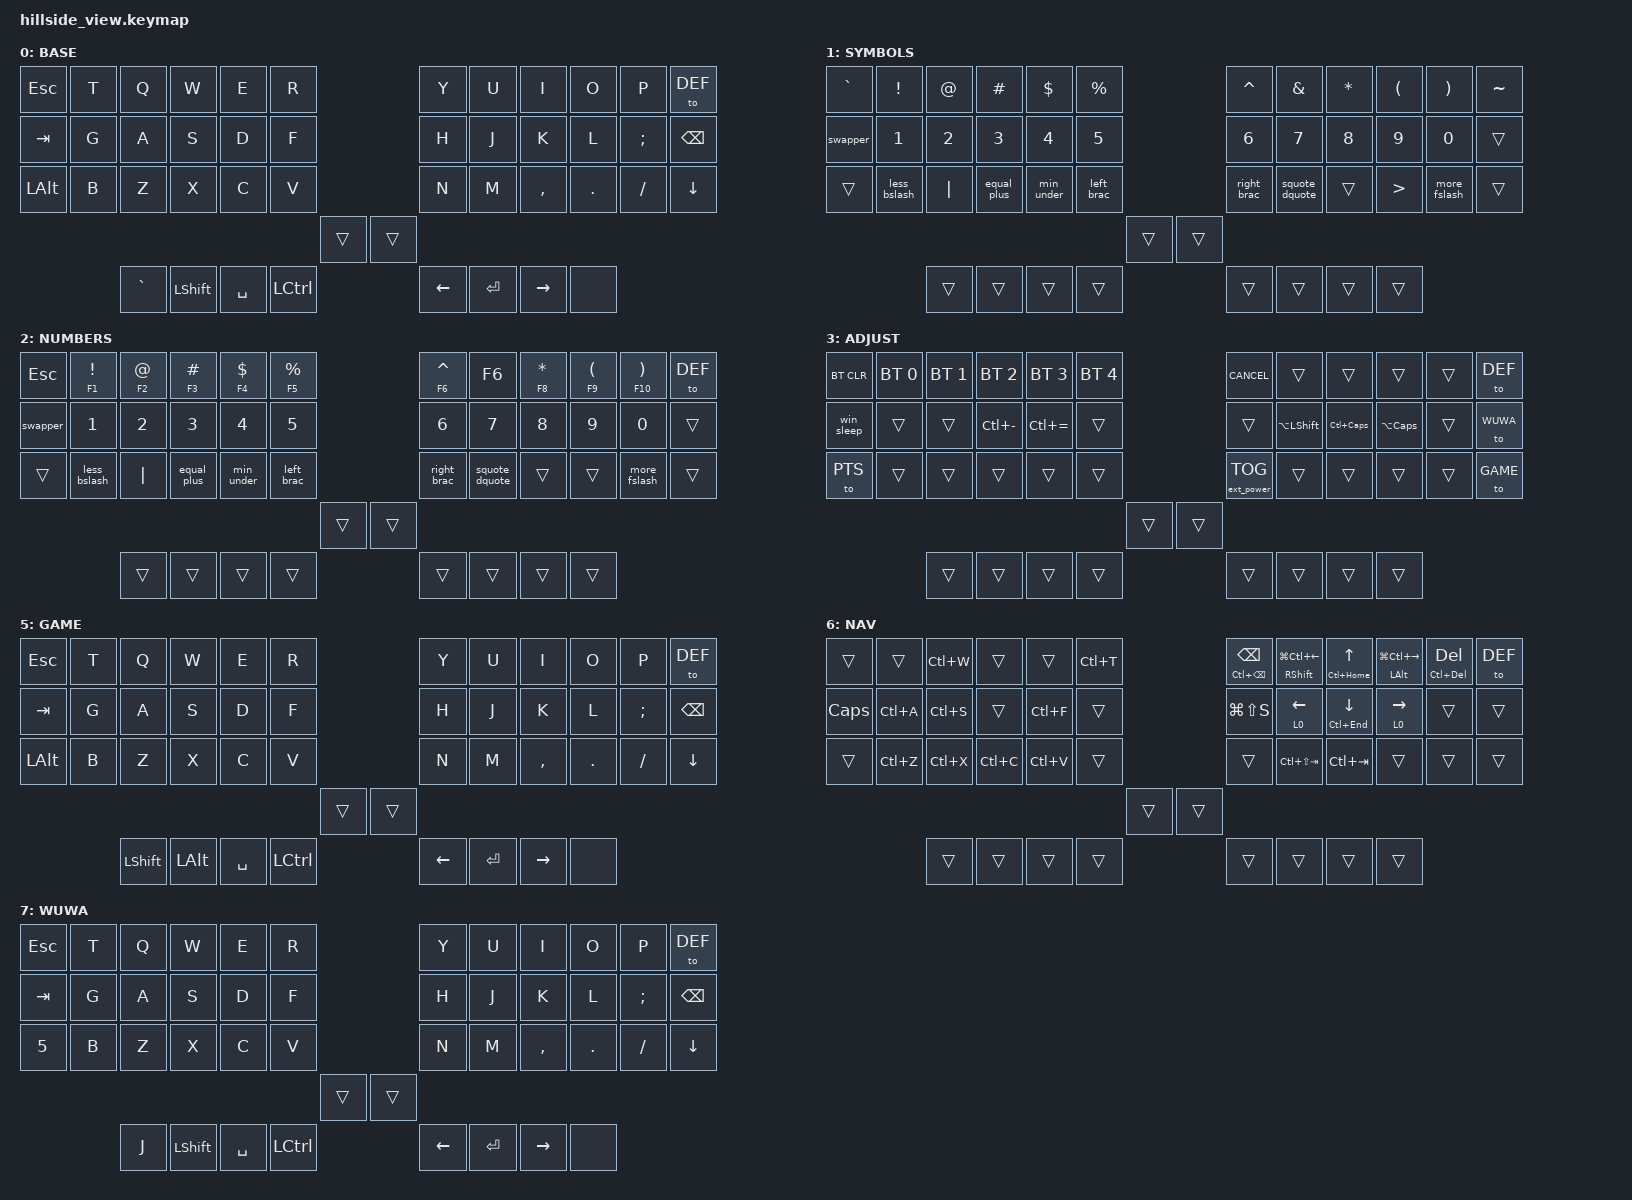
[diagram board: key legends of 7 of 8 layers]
#include <behaviors.dtsi>
#include <dt-bindings/zmk/keys.h>
#include <dt-bindings/zmk/bt.h>
#include <dt-bindings/zmk/rgb.h>
#include <dt-bindings/zmk/ext_power.h>
#include <dt-bindings/zmk/outputs.h>

#include "helpers.h"
#include "../zmk-nodefree-config/helper.h"
#include "../zmk-nodefree-config/keypos_def/keypos_46keys_hillside.h"

// #include "combos.dtsi"
#include "pts.dtsi"
#include "mouse.dtsi"

/* Defines */

#define XXX &none
#define ___ &trans

#define QUICK_TAP_MS 175

&sk {  // sticky-key config
    release-after-ms = <900>;  // release after 0.6s
    quick-release;             // no double capitalization when rolling keys
};

&sl {  // sticky-layer config
    ignore-modifiers;          // allow chording sticky mods & layers
};

&lt {  // layer-tap config
    flavor = "balanced";
    tapping-term-ms = <200>;
    quick-tap-ms = <QUICK_TAP_MS>;
};



// Layes. If you need to modify layers it's easier to refer to them via names, such as SYM for symbol and NUM for numbrs.
// Alias your layers with names in the section below
#define DEF 0
#define SYM 1
#define NUM 2
#define ADJ 3
#define PTS 4
#define GAME 5
#define WUWA 7
#define NAV 6


/* End of Defines */


// Q: What are those things starting with &? 
// A: Keywords that start with & are "behaviors". Behaviors are the main way to configure your keymap. 
//    The most common is called &kp which stands for key press. There several built-in bevaiors and also unlimitted number of ones you can create.
// Q: What are available built-in bevaiors?
// A: Here is a list of most common ones:
//   &kp - key press
//   &mo - momentary turn on the layer
//   &to - toggle a layer
//   &lt - layer tap; tap for a key pres and hold for a layer
//   &mt - mod tap; hold for modifier, tap for a key press
//   &sk - sticky key; sticky modifier



/*                                      46 KEY MATRIX / LAYOUT MAPPING

  ╭────────────────────────╮               ╭────────────────────────╮
  │  0   1   2   3   4   5 │               │  6   7   8   9  10  11 │
  │ 12  13  14  15  16  17 ╰──╮         ╭──╯ 18  19  20  21  22  23 │
  │ 24  25  26  27  28  29  36╰────┬────╯37  30  31  32  33  34  35 │
  ╰───────────────╮ 38  39  40  41 │ 42  43  44  45 ╭───────────────╯
                  ╰────────────────┴────────────────╯
                  
 ╭─────────────────────────╮               ╭─────────────────────────╮
 │ LT5 LT4 LT3 LT2 LT1 LT0 │               │ RT0 RT1 RT2 RT3 RT4 RT5 │
 │ LM5 LM4 LM3 LM2 LM1 LM0 ╰──╮         ╭──╯ RM0 RM1 RM2 RM3 RM4 RM5 │
 │ LB5 LB4 LB3 LB2 LB1 LB0 LH4╰────┬────╯RH4 RB0 RB1 RB2 RB3 RB4 RB5 │
 ╰───────────────╮ LH3 LH2 LH1 LH0 │ RH0 RH1 RH2 RH3 ╭───────────────╯
                 ╰─────────────────┴───── ───────────╯
 T : Top
 M : Middle
 B : Bottom
 H : Hand
 P : Palm
*/

#undef COMBO_HOOK
#define COMBO_HOOK global-quick-tap-ms = <150>;

#define COMBO_TERM_FAST 18
#define COMBO_TERM_SLOW 30
#define COMBO_TERM_SLOWW 90

// make homerow combos tap-only (so HRMs can be chorded instantaneously)
// #define HRC_TAB    &hml         LA(LCTRL) TAB
// #define HRC_REPEAT &hml_repeat  LS(LCTRL) 0
// #define HRC_LPAR   &hmr_lpar_lt RS(LCTRL) 0
// #define HRC_RPAR   &hmr_rpar_gt LA(LCTRL) 0



/* Horizontal combos - left hand */
// ZMK_COMBO(lpar,  &kp LPAR,      LM1 LM2,     DEF SYM NUM, COMBO_TERM_SLOWW)
// ZMK_COMBO(minus, &kp MINUS,     LM2 LM3,     DEF SYM NUM, COMBO_TERM_SLOWW)

/* Horizontal combos - right hand */
// ZMK_COMBO(rpar,  &kp RPAR,      RM1 RM2,     DEF SYM NUM, COMBO_TERM_SLOWW)
// ZMK_COMBO(sqt,   &kp SQT,       RM2 RM3,     DEF SYM NUM, COMBO_TERM_SLOWW)
// ZMK_COMBO(dqt,   &kp DQT,       RM3 RM4,     DEF SYM NUM, COMBO_TERM_SLOWW)


/* Vertical combos - left hand */
// ZMK_COMBO(excl,  &kp EXCL,      LT4 LM4,     DEF     NUM, COMBO_TERM_SLOW)
// ZMK_COMBO(at,    &kp AT,        LT3 LM3,     DEF     NUM, COMBO_TERM_SLOW)
// ZMK_COMBO(hash,  &kp POUND,     LT2 LM2,     DEF     NUM, COMBO_TERM_SLOW)
// ZMK_COMBO(dllr,  &kp DLLR,      LT1 LM1,     DEF     NUM, COMBO_TERM_SLOW)
// ZMK_COMBO(prcnt, &kp PRCNT,     LT0 LM0,     DEF     NUM, COMBO_TERM_SLOW)

// ZMK_COMBO(grave, &kp EQUAL,     LM4 LB4,     DEF     NUM, COMBO_TERM_SLOW)
// ZMK_COMBO(bslh,  &kp BSLH,      LM3 LB3,     DEF     NUM, COMBO_TERM_SLOW)
//  ZMK_COMBO(under, &kp UNDER,     LM2 LB2,     DEF     NUM, COMBO_TERM_SLOW)
//  ZMK_COMBO(minus, &kp MINUS,     LM1 LB1,     DEF     NUM, COMBO_TERM_SLOW)
// ZMK_COMBO(tilde, &kp CARET,  LM0 LB0,     DEF     NUM, COMBO_TERM_SLOW)

/* Vertical combos - right hand */
// ZMK_COMBO(caret, &kp CARET,     RT0 RM0,     DEF     NUM, COMBO_TERM_SLOW)
// ZMK_COMBO(amps,  &kp AMPS,      RT1 RM1,     DEF     NUM, COMBO_TERM_SLOW)
// ZMK_COMBO(astrk, &kp ASTRK,     RT2 RM2,     DEF     NUM, COMBO_TERM_SLOW)
// ZMK_COMBO(plus,  &kp PLUS,      RT3 RM3,     DEF     NUM, COMBO_TERM_SLOW)
// ZMK_COMBO(equal, &kp EQUAL,     RT4 RM4,     DEF     NUM, COMBO_TERM_SLOW)

// ZMK_COMBO(under, &kp UNDER,     RM0 RB0,     DEF     NUM, COMBO_TERM_SLOW)
//  ZMK_COMBO(sqt,     &kp SQT,     RM1 RB1,     DEF     NUM, COMBO_TERM_SLOW)
//  ZMK_COMBO(dqt,     &kp DQT,     RM2 RB2,     DEF     NUM, COMBO_TERM_SLOW)
// ZMK_COMBO(fslh,    &kp FSLH,    RM3 RB3,     DEF     NUM, COMBO_TERM_SLOW)
// ZMK_COMBO(under, &kp UNDER,     RM4 RB4,     DEF     NUM, COMBO_TERM_SLOW)


  /* Homerow mods */

#define KEYS_L LT0 LT1 LT2 LT3 LT4 LT5 LM0 LM1 LM2 LM3 LM4 LM5 LB0 LB1 LB2 LB3 LB4 LB5 // left hand
#define KEYS_R RT0 RT1 RT2 RT3 RT4 RT5 RM0 RM1 RM2 RM3 RM4 RM5 RB0 RB1 RB2 RB3 RB4 RB5 // right hand
#define THUMBS LH4 LH3 LH2 LH1 LH0 RH0 RH1 RH2 RH3 RH4                                     // thumbs

#define MAKE_HRM(NAME, HOLD, TAP, TRIGGER_POS) \
    ZMK_BEHAVIOR(NAME, hold_tap, \
        flavor = "balanced"; \
        tapping-term-ms = <280>; \
        quick-tap-ms = <QUICK_TAP_MS>; \
        global-quick-tap-ms = <150>; \
        bindings = <HOLD>, <TAP>; \
        hold-trigger-key-positions = <TRIGGER_POS>; \
        hold-trigger-on-release; \
    )
MAKE_HRM(hml, &kp, &kp, KEYS_R THUMBS)  // left-hand HRMs
MAKE_HRM(hmr, &kp, &kp, KEYS_L THUMBS)  // right-hand HRMs


/* Caps-word, num-word */

// tap: sticky-shift | shift + tap/ double-tap: caps-word | hold: shift
ZMK_BEHAVIOR(smart_shft, mod_morph,
    bindings = <&sk LSHFT>, <&caps_word>;
    mods = <(MOD_LSFT)>;
)
&caps_word {  // mods deactivate caps-word, requires PR #1451
    /delete-property/ ignore-modifiers;
};

// tap: num-word | double-tap: sticky num-layer | hold: num-layer
#define SMART_NUM &smart_num NUM 0
ZMK_BEHAVIOR(smart_num, hold_tap,
    flavor = "balanced";
    tapping-term-ms = <200>;
    quick-tap-ms = <QUICK_TAP_MS>;
    bindings = <&mo>, <&num_dance>;
)
ZMK_BEHAVIOR(num_dance, tap_dance,
    tapping-term-ms = <200>;
    bindings = <&num_word>, <&sl NUM>;  // reverse this for sticky-num on single tap
)
&num_word {  // num-word, requires PR #1451
    layers = <NUM>;
    continue-list = <BSPC DEL DOT COMMA PLUS MINUS STAR FSLH EQUAL>;
};


// tap: space | shift + tap: dot -> space -> sticky shift | hold: activate layer
/*
ZMK_BEHAVIOR(lt_spc, hold_tap,
    flavor = "balanced";
    tapping-term-ms = <200>;
    quick-tap-ms = <QUICK_TAP_MS>;
    bindings = <&mo>, <&spc_morph>;
)
*/

ZMK_BEHAVIOR(lt_spc, mod_morph,
    bindings = <&kp SPACE>, <&spc_morph>;
    mods = <(MOD_LSFT|MOD_RSFT)>;
)
ZMK_BEHAVIOR(spc_morph, mod_morph,
    bindings = <&kp SPACE>, <&dot_spc>;
    mods = <(MOD_LSFT|MOD_RSFT)>;
)
ZMK_BEHAVIOR(dot_spc, macro,
    wait-ms = <0>;
    tap-ms = <5>;
    bindings = <&kp DOT &kp SPACE &sk LSHFT>;
)


/* Nav cluster */

// long-tap action on hold, short-tap action on all interrupts
#define MT_CORE \
    flavor = "tap-preferred"; \
    tapping-term-ms = <220>; \
    quick-tap-ms = <220>; \
    hold-trigger-key-positions = <0>;

&mt { MT_CORE };
ZMK_BEHAVIOR(mt_home, hold_tap, bindings = <&masked_home>, <&kp>; MT_CORE)
ZMK_BEHAVIOR(mt_end,  hold_tap,  bindings = <&masked_end>, <&kp>; MT_CORE)

#define NAV_LEFT  &mt_home 0   LEFT    // tap: left  | long-tap: beginning of line
#define NAV_RIGHT &mt_end 0    RIGHT   // tap: right | long-tap: end       of line
#define NAV_UP    &mt LC(HOME) UP      // tap: up    | long-tap: beginning of document
#define NAV_DOWN  &mt LC(END)  DOWN    // tap: down  | long-tap: end       of document
#define NAV_BSPC  &mt LC(BSPC) BSPC    // tap: bspc  | long-tap: delete word backward
#define NAV_DEL   &mt LC(DEL)  DEL     // tap: del   | long-tap: delete word forward

// mask CTRL when holding left/right to avoid accidental jumps to beginning/end of document
#define MASK_MODS(NAME, MODS, BINDING) \
    ZMK_BEHAVIOR(NAME, mod_morph, \
        bindings = <BINDING>, <BINDING>; \
        mods = <MODS>; \
    )
MASK_MODS(masked_home, (MOD_LCTL), &kp HOME)
MASK_MODS(masked_end,  (MOD_LCTL), &kp END)


  /* Custom behaviors */

// tap: left-parenthesis | shft + tap: less-than
ZMK_BEHAVIOR(lpar_lt, mod_morph,
    bindings = <&kp LPAR>, <&kp LT>;
    mods = <(MOD_LSFT|MOD_RSFT)>;
)

// tap: right-parenthesis | shft + tap: greater-than
ZMK_BEHAVIOR(rpar_gt, mod_morph,
    bindings = <&kp RPAR>, <&kp GT>;
    mods = <(MOD_LSFT|MOD_RSFT)>;
)

ZMK_BEHAVIOR(win_sleep, macro,
    wait-ms = <500>;
    tap-ms = <50>;
    bindings = <&kp LG(X) &kp U &kp S>;
)

ZMK_BEHAVIOR(min_under, tap_dance,
    tapping-term-ms = <300>;
    bindings = <&kp MINUS>, <&kp UNDERSCORE>;
)
ZMK_BEHAVIOR(equal_plus, tap_dance,
    tapping-term-ms = <300>;
    bindings = <&kp EQUAL>, <&kp PLUS>;
)
ZMK_BEHAVIOR(squote_dquote, tap_dance,
    tapping-term-ms = <300>;
    bindings = <&kp SQT>, <&kp DQT>;
)
ZMK_BEHAVIOR(left_brac, tap_dance,
    tapping-term-ms = <300>;
    bindings = <&kp LEFT_BRACKET>, <&kp LEFT_BRACE>;
)
ZMK_BEHAVIOR(right_brac, tap_dance,
    tapping-term-ms = <300>;
    bindings = <&kp RIGHT_BRACKET>, <&kp RIGHT_BRACE>;
)
ZMK_BEHAVIOR(less_bslash, tap_dance,
    tapping-term-ms = <300>;
    bindings = <&kp LESS_THAN>, <&kp BACKSLASH>;
)
ZMK_BEHAVIOR(more_fslash, tap_dance,
    tapping-term-ms = <300>;
    bindings = <&kp GT>, <&kp FSLH>;
)


// Alt+Tab swapper, requires PR #1366
ZMK_BEHAVIOR(swapper, tri_state,
    bindings = <&kt LALT>, <&kp TAB>, <&kt LALT>;
    ignored-key-positions = <LT2>;
)

  // misc aliases
#define CANCEL      &kp K_CANCEL             // cancel caps-word, num-word
#define DSK_PREV    &hmr RSHFT LG(LC(LEFT))  // previous desktop
#define DSK_NEXT    &hmr LALT LG(LC(RIGHT))  // next     desktop

// ZMK_CONDITIONAL_LAYER(SYM NUM, ADJ)  // SYM + NUM --> ADJ

/ {
  
  conditional_layers {
    compatible = "zmk,conditional-layers";
    tri_layer {
      if-layers = <SYM NUM>;
      then-layer = <ADJ>;
    };
  };

  behaviors {
    // Hold tap behavior which will allow us to have a different key whether the key is tapped or held
    // https://zmk.dev/docs/behaviors/hold-tap
    ht: hold_tap {
      compatible = "zmk,behavior-hold-tap";
      label = "HOLD_TAP";
      #binding-cells = <2>;
      tapping_term_ms = <200>;
      quick_tap_ms = <200>;
      flavor = "tap-preferred";
      bindings = <&kp>, <&kp>;
    };
  };

  keymap {
    compatible = "zmk,keymap";
    default_layer {
      label = "BASE";
      bindings = <


/*
      // ╭─────────────┬─────────────┬─────────────┬─────────────┬─────────────┬─────────────╮                                      ╭─────────────┬─────────────┬─────────────┬─────────────┬─────────────┬────────────╮
             &kp ESC        &kp Q         &kp W         &kp E         &kp R         &kp T                                                &kp Y         &kp U         &kp I         &kp O        &kp P        &kp DEL    
      // ├─────────────┼─────────────┼─────────────┼─────────────┼─────────────┼─────────────┤                                      ├─────────────┼─────────────┼─────────────┼─────────────┼─────────────┼────────────┤
             &kp TAB     &hml LSHFT A  &hml LALT S   &hml LCTRL D  &hml LGUI F      &kp G                                                &kp H      &hmr RGUI J   &hmr RCTRL K  &hmr RALT L &hmr RSHFT SEMI  &kp BSPC    
      // ├─────────────┼─────────────┼─────────────┼─────────────┼─────────────┼─────────────┤  ╭─────────────╮     ╭─────────────╮ ├─────────────┼─────────────┼─────────────┼─────────────┼─────────────┼────────────┤
              &kp UP         &kp Z         &kp X         &kp C         &kp V        &kp B                                                &kp N         &kp M        &kp COMMA    &kp PERIOD     &kp FSLH     &kp DOWN  
                                                                                                      ___                 ___                                                                                         
      // ╰─────────────┴─────────────┼─────────────┼─────────────┼─────────────┼─────────────┤  ╰─────────────╯     ╰─────────────╯ ├─────────────┼─────────────┼─────────────┼─────────────┼─────────────┴────────────╯
                                         &mo NAV       &mo SYM      &kp ENTER    &smart_shft                                            &kp LEFT      &lt_spc      SMART_NUM     &kp RIGHT
      //                             ╰─────────────┴─────────────┴─────────────┴─────────────╯                                      ╰─────────────┴─────────────┴─────────────┴─────────────╯
      >;
*/

      // ╭─────────────┬─────────────┬─────────────┬─────────────┬─────────────┬─────────────╮                                      ╭─────────────┬─────────────┬─────────────┬─────────────┬─────────────┬────────────╮
             &kp ESC        &kp T         &kp Q         &kp W         &kp E         &kp R                                                &kp Y         &kp U         &kp I         &kp O        &kp P        &to DEF    
      // ├─────────────┼─────────────┼─────────────┼─────────────┼─────────────┼─────────────┤                                      ├─────────────┼─────────────┼─────────────┼─────────────┼─────────────┼────────────┤
             &kp TAB        &kp G         &kp A         &kp S         &kp D         &kp F                                                &kp H         &kp J         &kp K         &kp L        &kp SEMI     &kp BSPC    
      // ├─────────────┼─────────────┼─────────────┼─────────────┼─────────────┼─────────────┤  ╭─────────────╮     ╭─────────────╮ ├─────────────┼─────────────┼─────────────┼─────────────┼─────────────┼────────────┤
             &kp LALT       &kp B          &kp Z         &kp X        &kp C         &kp V                                                &kp N         &kp M        &kp COMMA     &kp DOT       &kp FSLH     &kp DOWN  
                                                                                                      ___                 ___                                                                                         
      // ╰─────────────┴─────────────┼─────────────┼─────────────┼─────────────┼─────────────┤  ╰─────────────╯     ╰─────────────╯ ├─────────────┼─────────────┼─────────────┼─────────────┼─────────────┴────────────╯
                                         &kp GRAVE    &kp LSHFT     &kp SPACE     &kp LCTRL                                              &kp LEFT     &kp ENTER     &kp RIGHT        XXX
      //                             ╰─────────────┴─────────────┴─────────────┴─────────────╯                                      ╰─────────────┴─────────────┴─────────────┴─────────────╯
      >;

      // Bindings for encoders, if you don't have encoders you can remove this line from all layers. If you leave it here it won't affect your keymap.
      sensor-bindings = <&inc_dec_kp C_VOL_DN C_VOL_UP &inc_dec_kp PG_UP PG_DN>;
    };
    sym_layer {
      label = "SYMBOLS";
      bindings = <
      // ╭─────────────┬─────────────┬─────────────┬─────────────┬─────────────┬─────────────╮                                      ╭─────────────┬─────────────┬─────────────┬─────────────┬─────────────┬────────────╮
	    &kp GRAVE     &kp EXCL       &kp AT      &kp POUND      &kp DLLR     &kp PRCNT                                            &kp CARET      &kp AMPS     &kp ASTRK      &kp LPAR      &kp RPAR      &kp TILDE
      // ├─────────────┼─────────────┼─────────────┼─────────────┼─────────────┼─────────────┤                                      ├─────────────┼─────────────┼─────────────┼─────────────┼─────────────┼────────────┤
             &swapper       &kp N1         &kp N2        &kp N3       &kp N4        &kp N5                                               &kp N6        &kp N7         &kp N8        &kp N9        &kp N0         ___
      // ├─────────────┼─────────────┼─────────────┼─────────────┼─────────────┼─────────────┤  ╭─────────────╮     ╭─────────────╮ ├─────────────┼─────────────┼─────────────┼─────────────┼─────────────┼────────────┤
               ___       &less_bslash    &kp PIPE    &equal_plus    &min_under    &left_brac                                          &right_brac  &squote_dquote     ___          &kp GT     &more_fslash      ___                                                                                                         ___                ___                                                                                          
      // ╰─────────────┴─────────────┼─────────────┼─────────────┼─────────────┼─────────────┤  ╰─────────────╯     ╰─────────────╯ ├─────────────┼─────────────┼─────────────┼─────────────┼─────────────┴────────────╯
                                           ___           ___           ___           ___                                                 ___          ___            ___           ___         
      //                             ╰─────────────┴─────────────┴─────────────┴─────────────╯                                      ╰─────────────┴─────────────┴─────────────┴─────────────╯
      >;
      sensor-bindings = <&inc_dec_kp C_VOL_DN C_VOL_UP &inc_dec_kp PG_UP PG_DN>;
    };
    num_layer {
      label = "NUMBERS";
      bindings = <
      // ╭─────────────┬─────────────┬─────────────┬─────────────┬─────────────┬─────────────╮                                      ╭─────────────┬─────────────┬─────────────┬─────────────┬─────────────┬────────────╮
             &kp ESC     &ht F1 EXCL    &ht F2 AT    &ht F3 POUND  &ht F4 DLLR  &ht F5 PRCNT                                          &ht F6 CARET  &kp F6  &ht F8 ASTRK   &ht F9 LPAR   &ht F10 RPAR    &to DEF
      // ├─────────────┼─────────────┼─────────────┼─────────────┼─────────────┼─────────────┤                                      ├─────────────┼─────────────┼─────────────┼─────────────┼─────────────┼────────────┤
            &swapper        &kp N1        &kp N2        &kp N3        &kp N4       &kp N5                                                &kp N6        &kp N7        &kp N8        &kp N9        &kp N0         ___
      // ├─────────────┼─────────────┼─────────────┼─────────────┼─────────────┼─────────────┤  ╭─────────────╮     ╭─────────────╮ ├─────────────┼─────────────┼─────────────┼─────────────┼─────────────┼────────────┤
               ___       &less_bslash    &kp PIPE    &equal_plus    &min_under    &left_brac                                          &right_brac  &squote_dquote     ___           ___       &more_fslash      ___                                                                                                        ___                ___                                                                                          
      // ╰─────────────┴─────────────┼─────────────┼─────────────┼─────────────┼─────────────┤  ╰─────────────╯     ╰─────────────╯ ├─────────────┼─────────────┼─────────────┼─────────────┼─────────────┴────────────╯
                                           ___            ___           ___           ___                                                ___          ___            ___           ___         
      //                             ╰─────────────┴─────────────┴─────────────┴─────────────╯                                      ╰─────────────┴─────────────┴─────────────┴─────────────╯
      >;
      sensor-bindings = <&inc_dec_kp C_VOL_DN C_VOL_UP &inc_dec_kp PG_UP PG_DN>;
    };
    adj_layer {
      label = "ADJUST";
      bindings = <
      // ╭─────────────┬─────────────┬─────────────┬─────────────┬─────────────┬─────────────╮                                      ╭─────────────┬─────────────┬─────────────┬─────────────┬─────────────┬────────────╮
           &bt BT_CLR  &bt BT_SEL 0    &bt BT_SEL 1 &bt BT_SEL 2  &bt BT_SEL 3  &bt BT_SEL 4                                             CANCEL         ___           ___           ___           ___        &to DEF
      // ├─────────────┼─────────────┼─────────────┼─────────────┼─────────────┼─────────────┤                                      ├─────────────┼─────────────┼─────────────┼─────────────┼─────────────┼────────────┤
	   &win_sleep        ___           ___      &kp LC(MINUS) &kp LC(EQUAL)      ___                                                  ___      &kp LA(LSHFT)  &kp LC(CAPS)  &kp LA(CAPS)      ___        &to WUWA
      // ├─────────────┼─────────────┼─────────────┼─────────────┼─────────────┼─────────────┤  ╭─────────────╮     ╭─────────────╮ ├─────────────┼─────────────┼─────────────┼─────────────┼─────────────┼────────────┤
             &to PTS         ___           ___           ___           ___           ___                                           &ext_power EP_TOG    ___           ___           ___           ___        &to GAME
                                                                                                      ___                ___                                                                                    
      // ╰─────────────┴─────────────┼─────────────┼─────────────┼─────────────┼─────────────┤  ╰─────────────╯     ╰─────────────╯ ├─────────────┼─────────────┼─────────────┼─────────────┼─────────────┴────────────╯
                                           ___           ___           ___           ___                                                  ___           ___           ___           ___           
      //                             ╰─────────────┴─────────────┴─────────────┴─────────────╯                                      ╰─────────────┴─────────────┴─────────────┴─────────────╯
      >;
      sensor-bindings = <&inc_dec_kp C_VOL_DN C_VOL_UP &inc_dec_kp PG_UP PG_DN>;
    };
    pts_layer {
      label = "PTS";
      bindings = <
      // ╭─────────────┬─────────────┬─────────────┬─────────────┬─────────────┬─────────────╮                                      ╭─────────────┬─────────────┬─────────────┬─────────────┬─────────────┬────────────╮
            &kp LC(S)     &dup_merge   &transf_warp   &move_full   &soft_vivid  &multiply_screen                                        &kp LC(K)       U_WH_U        U_MS_U        U_WH_D         &kp F       &to DEF
      // ├─────────────┼─────────────┼─────────────┼─────────────┼─────────────┼─────────────┤                                      ├─────────────┼─────────────┼─────────────┼─────────────┼─────────────┼────────────┤
	  &kp LC(LA(Q)) &kp new_layer     &kp L        &kp Z       &ht GRAVE B      &kp O                                               &swapper       U_MS_L        U_MS_D        U_MS_R         ___           ___
      // ├─────────────┼─────────────┼─────────────┼─────────────┼─────────────┼─────────────┤  ╭─────────────╮     ╭─────────────╮ ├─────────────┼─────────────┼─────────────┼─────────────┼─────────────┼────────────┤
          &kp LC(LA(G))  &desel_del    &copy_paste    &kp LS(DOT)  &kp LC(Z)      &g_normal                                              &kp ESC        U_BTN1        U_BTN2        U_BTN3         ___           ___
                                                                                                      ___                ___                                                                                   
      // ╰─────────────┴─────────────┼─────────────┼─────────────┼─────────────┼─────────────┤  ╰─────────────╯     ╰─────────────╯ ├─────────────┼─────────────┼─────────────┼─────────────┼─────────────┴────────────╯
                                        &kp LCTRL     &kp LSHFT      &kp LALT     &kp ENTER                                                ___          ___           ___           ___           
      //                             ╰─────────────┴─────────────┴─────────────┴─────────────╯                                      ╰─────────────┴─────────────┴─────────────┴─────────────╯
      >;
      sensor-bindings = <&inc_dec_kp LEFT_BRACKET RIGHT_BRACKET &inc_dec_kp C_VOL_UP C_VOL_DN>;
    };
    game_layer {
      label = "GAME";
      bindings = <

      // ╭─────────────┬─────────────┬─────────────┬─────────────┬─────────────┬─────────────╮                                      ╭─────────────┬─────────────┬─────────────┬─────────────┬─────────────┬────────────╮
             &kp ESC        &kp T         &kp Q         &kp W         &kp E         &kp R                                                &kp Y         &kp U         &kp I         &kp O        &kp P        &to DEF    
      // ├─────────────┼─────────────┼─────────────┼─────────────┼─────────────┼─────────────┤                                      ├─────────────┼─────────────┼─────────────┼─────────────┼─────────────┼────────────┤
             &kp TAB        &kp G         &kp A         &kp S         &kp D         &kp F                                                &kp H         &kp J         &kp K         &kp L        &kp SEMI     &kp BSPC    
      // ├─────────────┼─────────────┼─────────────┼─────────────┼─────────────┼─────────────┤  ╭─────────────╮     ╭─────────────╮ ├─────────────┼─────────────┼─────────────┼─────────────┼─────────────┼────────────┤
             &kp LALT       &kp B          &kp Z         &kp X        &kp C         &kp V                                                &kp N         &kp M        &kp COMMA     &kp DOT       &kp FSLH     &kp DOWN  
                                                                                                      ___                 ___                                                                                         
      // ╰─────────────┴─────────────┼─────────────┼─────────────┼─────────────┼─────────────┤  ╰─────────────╯     ╰─────────────╯ ├─────────────┼─────────────┼─────────────┼─────────────┼─────────────┴────────────╯
                                         &kp LSHFT    &kp LALT     &kp SPACE     &kp LCTRL                                              &kp LEFT     &kp ENTER     &kp RIGHT        XXX
      //                             ╰─────────────┴─────────────┴─────────────┴─────────────╯                                      ╰─────────────┴─────────────┴─────────────┴─────────────╯
      >;
      sensor-bindings = <&inc_dec_kp C_VOL_DN C_VOL_UP &inc_dec_kp C_VOL_UP C_VOL_DN>;
    };

    nav_layer {
      label = "NAV";
      bindings = <
      // ╭─────────────┬─────────────┬─────────────┬─────────────┬─────────────┬─────────────╮                                      ╭─────────────┬─────────────┬─────────────┬─────────────┬─────────────┬────────────╮
               ___           ___        &kp LC(W)        ___           ___        &kp LC(T)                                             NAV_BSPC      DSK_PREV       NAV_UP       DSK_NEXT      NAV_DEL      &to DEF
      // ├─────────────┼─────────────┼─────────────┼─────────────┼─────────────┼─────────────┤                                      ├─────────────┼─────────────┼─────────────┼─────────────┼─────────────┼────────────┤
            &kp CAPS        &kp LC(A)     &kp LC(S)      ___        &kp LC(F)  	     ___                                      	     &kp LG(LS(S))    NAV_LEFT      NAV_DOWN     NAV_RIGHT        ___           ___
      // ├─────────────┼─────────────┼─────────────┼─────────────┼─────────────┼─────────────┤  ╭─────────────╮     ╭─────────────╮ ├─────────────┼─────────────┼─────────────┼─────────────┼─────────────┼────────────┤
               ___     	  &kp LC(Z)     &kp LC(X)     &kp LC(C)     &kp LC(V)        ___                                                  ___     &kp LC(LS(TAB)) &kp LC(TAB)       ___           ___           ___
                                                                                                      ___                ___                                                                                    
      // ╰─────────────┴─────────────┼─────────────┼─────────────┼─────────────┼─────────────┤  ╰─────────────╯     ╰─────────────╯ ├─────────────┼─────────────┼─────────────┼─────────────┼─────────────┴────────────╯
                                           ___           ___           ___           ___                                                  ___           ___           ___           ___           
      //                             ╰─────────────┴─────────────┴─────────────┴─────────────╯                                      ╰─────────────┴─────────────┴─────────────┴─────────────╯
      >;
      sensor-bindings = <&inc_dec_kp C_VOL_DN C_VOL_UP &inc_dec_kp PG_UP PG_DN>;
    };

    wuwa_layer {
      label = "WUWA";
      bindings = <

      // ╭─────────────┬─────────────┬─────────────┬─────────────┬─────────────┬─────────────╮                                      ╭─────────────┬─────────────┬─────────────┬─────────────┬─────────────┬────────────╮
             &kp ESC        &kp T         &kp Q         &kp W         &kp E         &kp R                                                &kp Y         &kp U         &kp I         &kp O        &kp P        &to DEF    
      // ├─────────────┼─────────────┼─────────────┼─────────────┼─────────────┼─────────────┤                                      ├─────────────┼─────────────┼─────────────┼─────────────┼─────────────┼────────────┤
             &kp TAB        &kp G         &kp A         &kp S         &kp D         &kp F                                                &kp H         &kp J         &kp K         &kp L        &kp SEMI     &kp BSPC    
      // ├─────────────┼─────────────┼─────────────┼─────────────┼─────────────┼─────────────┤  ╭─────────────╮     ╭─────────────╮ ├─────────────┼─────────────┼─────────────┼─────────────┼─────────────┼────────────┤
             &kp N5       &kp B          &kp Z         &kp X        &kp C         &kp V                                                &kp N         &kp M        &kp COMMA     &kp DOT       &kp FSLH     &kp DOWN  
                                                                                                      ___                 ___                                                                                         
      // ╰─────────────┴─────────────┼─────────────┼─────────────┼─────────────┼─────────────┤  ╰─────────────╯     ╰─────────────╯ ├─────────────┼─────────────┼─────────────┼─────────────┼─────────────┴────────────╯
                                         &kp J    &kp LSHFT     &kp SPACE     &kp LCTRL                                              &kp LEFT     &kp ENTER     &kp RIGHT        XXX
      //                             ╰─────────────┴─────────────┴─────────────┴─────────────╯                                      ╰─────────────┴─────────────┴─────────────┴─────────────╯
      >;
      sensor-bindings = <&inc_dec_kp C_VOL_DN C_VOL_UP &inc_dec_kp C_VOL_UP C_VOL_DN>;
    };
  };
};
